# RP2350 register map
Vendor: Raspberry Pi; Series: RP; File version: 0.1
CPU: CM33 r1p0, little endian, MPU, FPU, DSP, VTOR, 4 interrupt priority bits, 52 interrupts, 8 SAU regions
Registers are 32-bit, read-write, reset 0x0 unless marked. A register's access mark holds for its fields unless they carry their own. Offsets are from the block's base; [hi:lo] are bit positions; {n}, {i} and the like mark numbered series; 'fields as' and 'values as' point back to an identical list.

## USB — USB FS/LS controller device registers
Base 0x50110000
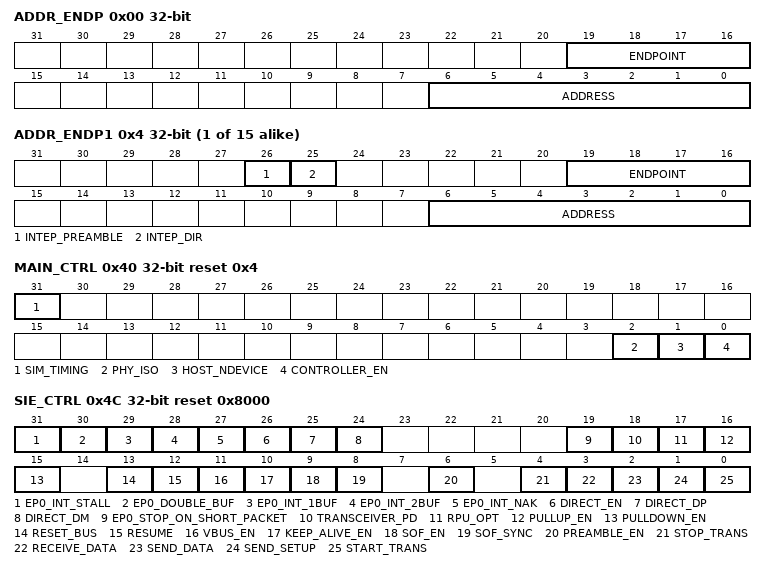
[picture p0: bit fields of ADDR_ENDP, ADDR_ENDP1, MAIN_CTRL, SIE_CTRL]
0x00 ADDR_ENDP — Device address and endpoint control
  [19:16] ENDPOINT — Device endpoint to send data to. Only valid for HOST mode.
  [6:0] ADDRESS — In device mode, the address that the device should respond to. Set in response to a SET_ADDR setup packet from the host. In host mode set to the address of the device to communicate with.
{0x0+4i} ADDR_ENDP{i} (i=1..15) — Interrupt endpoint {i}. Only valid for HOST mode.
  [26] INTEP_PREAMBLE — Interrupt EP requires preamble (is a low speed device on a full speed hub)
  [25] INTEP_DIR — Direction of the interrupt endpoint. In=0, Out=1
  [19:16] ENDPOINT — Endpoint number of the interrupt endpoint
  [6:0] ADDRESS — Device address
0x40 MAIN_CTRL reset 0x4 — Main control register
  [31] SIM_TIMING — Reduced timings for simulation
  [2] PHY_ISO — Isolates USB phy after controller power-up Remove isolation once software has configured the controller Not isolated = 0, Isolated = 1
  [1] HOST_NDEVICE — Device mode = 0, Host mode = 1
  [0] CONTROLLER_EN — Enable controller
0x44 SOF_WR — Set the SOF (Start of Frame) frame number in the host controller. The SOF packet is sent every 1ms and the host will increment the frame number by 1 each time.
  [10:0] COUNT wo — Pre-defined description
0x48 SOF_RD — Read the last SOF (Start of Frame) frame number seen. In device mode the last SOF received from the host. In host mode the last SOF sent by the host.
  [10:0] COUNT ro — Pre-defined description
0x4C SIE_CTRL reset 0x8000 — SIE control register
  [31] EP0_INT_STALL — Device: Set bit in EP_STATUS_STALL_NAK when EP0 sends a STALL
  [30] EP0_DOUBLE_BUF — Device: EP0 single buffered = 0, double buffered = 1
  [29] EP0_INT_1BUF — Device: Set bit in BUFF_STATUS for every buffer completed on EP0
  [28] EP0_INT_2BUF — Device: Set bit in BUFF_STATUS for every 2 buffers completed on EP0
  [27] EP0_INT_NAK — Device: Set bit in EP_STATUS_STALL_NAK when EP0 sends a NAK
  [26] DIRECT_EN — Direct bus drive enable
  [25] DIRECT_DP — Direct control of DP
  [24] DIRECT_DM — Direct control of DM
  [19] EP0_STOP_ON_SHORT_PACKET — Device: Stop EP0 on a short packet.
  [18] TRANSCEIVER_PD — Power down bus transceiver
  [17] RPU_OPT — Device: Pull-up strength (0=1K2, 1=2k3)
  [16] PULLUP_EN — Device: Enable pull up resistor
  [15] PULLDOWN_EN — Host: Enable pull down resistors
  [13] RESET_BUS wo — Host: Reset bus
  [12] RESUME wo — Device: Remote wakeup. Device can initiate its own resume after suspend.
  [11] VBUS_EN — Host: Enable VBUS
  [10] KEEP_ALIVE_EN — Host: Enable keep alive packet (for low speed bus)
  [9] SOF_EN — Host: Enable SOF generation (for full speed bus)
  [8] SOF_SYNC — Host: Delay packet(s) until after SOF
  [6] PREAMBLE_EN — Host: Preable enable for LS device on FS hub
  [4] STOP_TRANS wo — Host: Stop transaction
  [3] RECEIVE_DATA — Host: Receive transaction (IN to host)
  [2] SEND_DATA — Host: Send transaction (OUT from host)
  [1] SEND_SETUP — Host: Send Setup packet
  [0] START_TRANS wo — Host: Start transaction
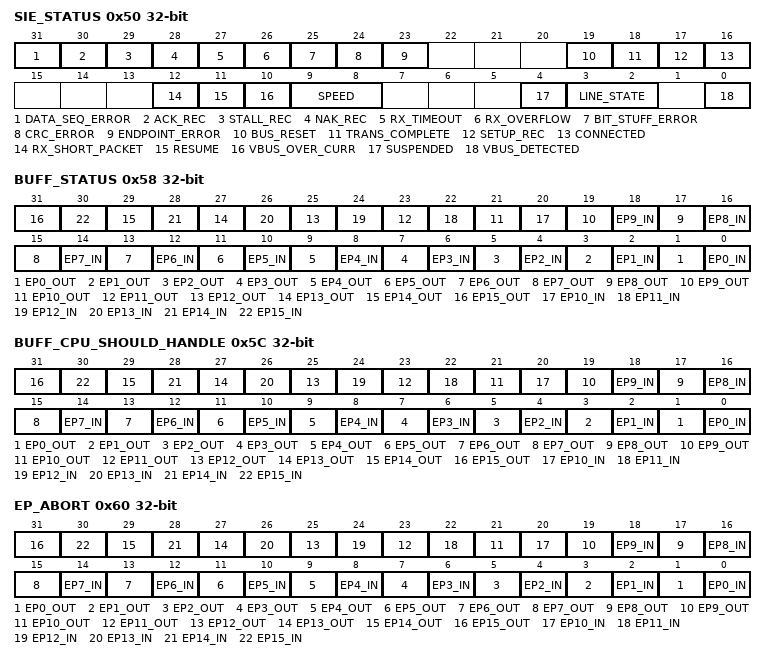
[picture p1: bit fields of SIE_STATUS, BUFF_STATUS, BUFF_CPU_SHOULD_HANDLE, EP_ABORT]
0x50 SIE_STATUS
  [31] DATA_SEQ_ERROR write-1-clears — Data Sequence Error. The device can raise a sequence error in the following conditions: * A SETUP packet is received followed by a DATA1 packet (data phase should always be DATA0) * An OUT packet is received from the host but doesn't match the data pid in the buffer control register read from DPSRAM The host can raise a data sequence error in the following conditions: * An IN packet from the device has the wrong data PID
  [30] ACK_REC write-1-clears — ACK received. Raised by both host and device.
  [29] STALL_REC write-1-clears — Host: STALL received
  [28] NAK_REC write-1-clears — Host: NAK received
  [27] RX_TIMEOUT write-1-clears — RX timeout is raised by both the host and device if an ACK is not received in the maximum time specified by the USB spec.
  [26] RX_OVERFLOW write-1-clears — RX overflow is raised by the Serial RX engine if the incoming data is too fast.
  [25] BIT_STUFF_ERROR write-1-clears — Bit Stuff Error. Raised by the Serial RX engine.
  [24] CRC_ERROR write-1-clears — CRC Error. Raised by the Serial RX engine.
  [23] ENDPOINT_ERROR write-1-clears — An endpoint has encountered an error. Read the ep_rx_error and ep_tx_error registers to find out which endpoint had an error.
  [19] BUS_RESET write-1-clears — Device: bus reset received
  [18] TRANS_COMPLETE write-1-clears — Transaction complete. Raised by device if: * An IN or OUT packet is sent with the `LAST_BUFF` bit set in the buffer control register Raised by host if: * A setup packet is sent when no data in or data out transaction follows * An IN packet is received and the `LAST_BUFF` bit is set in the buffer control register * An IN packet is received with zero length * An OUT packet is sent and the `LAST_BUFF` bit is set
  [17] SETUP_REC write-1-clears — Device: Setup packet received
  [16] CONNECTED ro — Device: connected
  [12] RX_SHORT_PACKET write-1-clears — Device or Host has received a short packet. This is when the data received is less than configured in the buffer control register. Device: If using double buffered mode on device the buffer select will not be toggled after writing status back to the buffer control register. This is to prevent any further transactions on that endpoint until the user has reset the buffer control registers. Host: the current transfer will be stopped early.
  [11] RESUME write-1-clears — Host: Device has initiated a remote resume. Device: host has initiated a resume.
  [10] VBUS_OVER_CURR ro — VBUS over current detected
  [9:8] SPEED ro — Host: device speed. Disconnected = 00, LS = 01, FS = 10
  [4] SUSPENDED write-1-clears — Bus in suspended state. Valid for device. Device will go into suspend if neither Keep Alive / SOF frames are enabled.
  [3:2] LINE_STATE ro — USB bus line state
  [0] VBUS_DETECTED ro — Device: VBUS Detected
0x54 INT_EP_CTRL — interrupt endpoint control register
  [15:1] INT_EP_ACTIVE — Host: Enable interrupt endpoint 1 -> 15
0x58 BUFF_STATUS — Buffer status register. A bit set here indicates that a buffer has completed on the endpoint (if the buffer interrupt is enabled). It is possible for 2 buffers to be completed, so clearing the buffer status bit may instantly re set it on the next clock cycle.
  [2n+1] EP{n}_OUT write-1-clears (n=0..15) — Pre-defined description
  [2n] EP{n}_IN write-1-clears (n=0..15) — Pre-defined description
0x5C BUFF_CPU_SHOULD_HANDLE — Which of the double buffers should be handled. Only valid if using an interrupt per buffer (i.e. not per 2 buffers). Not valid for host interrupt endpoint polling because they are only single buffered.
  [2n+1] EP{n}_OUT ro (n=0..15) — Pre-defined description
  [2n] EP{n}_IN ro (n=0..15) — Pre-defined description
0x60 EP_ABORT — Device only: Can be set to ignore the buffer control register for this endpoint in case you would like to revoke a buffer. A NAK will be sent for every access to the endpoint until this bit is cleared. A corresponding bit in `EP_ABORT_DONE` is set when it is safe to modify the buffer control register.
  [2n+1] EP{n}_OUT (n=0..15) — Pre-defined description
  [2n] EP{n}_IN (n=0..15) — Pre-defined description
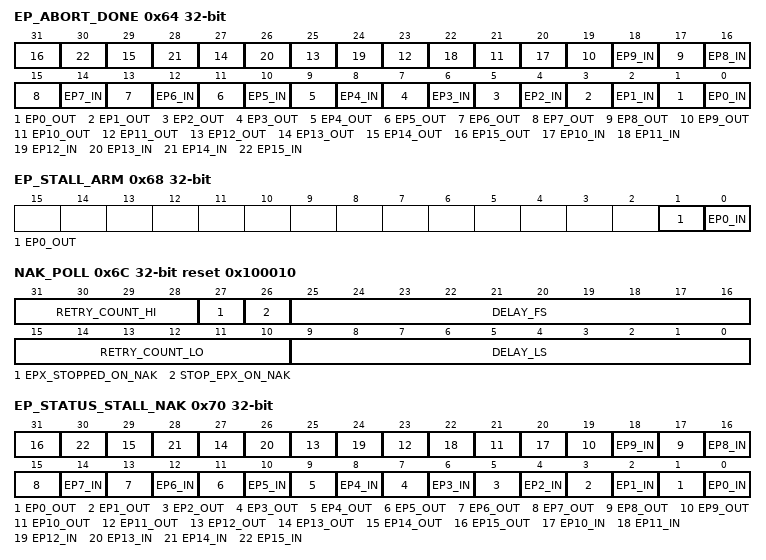
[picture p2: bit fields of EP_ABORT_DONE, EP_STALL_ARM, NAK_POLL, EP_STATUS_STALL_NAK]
0x64 EP_ABORT_DONE — Device only: Used in conjunction with `EP_ABORT`. Set once an endpoint is idle so the programmer knows it is safe to modify the buffer control register.
  fields as BUFF_STATUS
0x68 EP_STALL_ARM — Device: this bit must be set in conjunction with the `STALL` bit in the buffer control register to send a STALL on EP0. The device controller clears these bits when a SETUP packet is received because the USB spec requires that a STALL condition is cleared when a SETUP packet is received.
  [1] EP0_OUT — Pre-defined description
  [0] EP0_IN — Pre-defined description
0x6C NAK_POLL reset 0x100010 — Used by the host controller. Sets the wait time in microseconds before trying again if the device replies with a NAK.
  [31:28] RETRY_COUNT_HI ro — Bits 9:6 of nak_retry count
  [27] EPX_STOPPED_ON_NAK write-1-clears — EPX polling has stopped because a nak was received
  [26] STOP_EPX_ON_NAK — Stop polling epx when a nak is received
  [25:16] DELAY_FS — NAK polling interval for a full speed device
  [15:10] RETRY_COUNT_LO ro — Bits 5:0 of nak_retry_count
  [9:0] DELAY_LS — NAK polling interval for a low speed device
0x70 EP_STATUS_STALL_NAK — Device: bits are set when the `IRQ_ON_NAK` or `IRQ_ON_STALL` bits are set. For EP0 this comes from `SIE_CTRL`. For all other endpoints it comes from the endpoint control register.
  fields as BUFF_STATUS
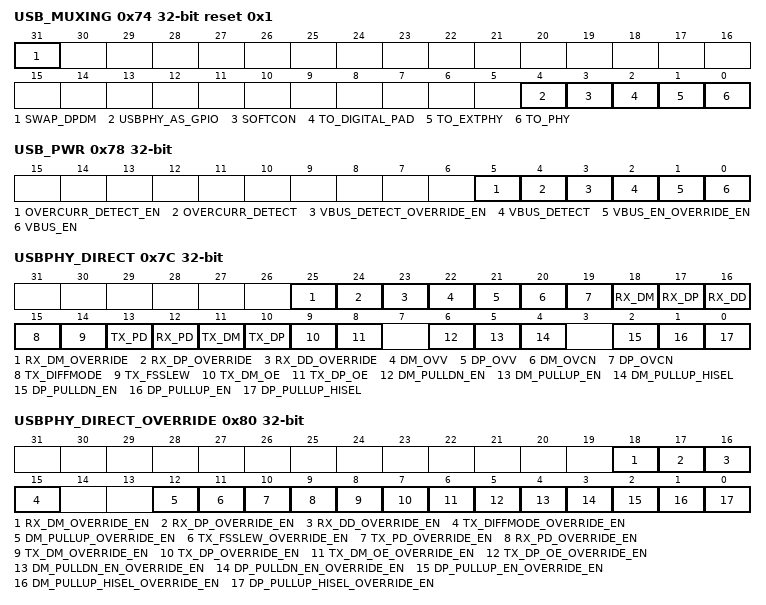
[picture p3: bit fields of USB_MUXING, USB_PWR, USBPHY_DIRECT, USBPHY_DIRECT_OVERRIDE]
0x74 USB_MUXING reset 0x1 — Where to connect the USB controller. Should be to_phy by default.
  [31] SWAP_DPDM — Swap the USB PHY DP and DM pins and all related controls and flip receive differential data. Can be used to switch USB DP/DP on the PCB. This is done at a low level so overrides all other controls.
  [4] USBPHY_AS_GPIO — Use the usb DP and DM pins as GPIO pins instead of connecting them to the USB controller.
  [3] SOFTCON — Pre-defined description
  [2] TO_DIGITAL_PAD — Pre-defined description
  [1] TO_EXTPHY — Pre-defined description
  [0] TO_PHY — Pre-defined description
0x78 USB_PWR — Overrides for the power signals in the event that the VBUS signals are not hooked up to GPIO. Set the value of the override and then the override enable to switch over to the override value.
  [5] OVERCURR_DETECT_EN — Pre-defined description
  [4] OVERCURR_DETECT — Pre-defined description
  [3] VBUS_DETECT_OVERRIDE_EN — Pre-defined description
  [2] VBUS_DETECT — Pre-defined description
  [1] VBUS_EN_OVERRIDE_EN — Pre-defined description
  [0] VBUS_EN — Pre-defined description
0x7C USBPHY_DIRECT — This register allows for direct control of the USB phy. Use in conjunction with usbphy_direct_override register to enable each override bit.
  [25] RX_DM_OVERRIDE — Override rx_dm value into controller
  [24] RX_DP_OVERRIDE — Override rx_dp value into controller
  [23] RX_DD_OVERRIDE — Override rx_dd value into controller
  [22] DM_OVV ro — DM over voltage
  [21] DP_OVV ro — DP over voltage
  [20] DM_OVCN ro — DM overcurrent
  [19] DP_OVCN ro — DP overcurrent
  [18] RX_DM ro — DPM pin state
  [17] RX_DP ro — DPP pin state
  [16] RX_DD ro — Differential RX
  [15] TX_DIFFMODE — TX_DIFFMODE=0: Single ended mode TX_DIFFMODE=1: Differential drive mode (TX_DM, TX_DM_OE ignored)
  [14] TX_FSSLEW — TX_FSSLEW=0: Low speed slew rate TX_FSSLEW=1: Full speed slew rate
  [13] TX_PD — TX power down override (if override enable is set). 1 = powered down.
  [12] RX_PD — RX power down override (if override enable is set). 1 = powered down.
  [11] TX_DM — Output data. TX_DIFFMODE=1, Ignored TX_DIFFMODE=0, Drives DPM only. TX_DM_OE=1 to enable drive. DPM=TX_DM
  [10] TX_DP — Output data. If TX_DIFFMODE=1, Drives DPP/DPM diff pair. TX_DP_OE=1 to enable drive. DPP=TX_DP, DPM=~TX_DP If TX_DIFFMODE=0, Drives DPP only. TX_DP_OE=1 to enable drive. DPP=TX_DP
  [9] TX_DM_OE — Output enable. If TX_DIFFMODE=1, Ignored. If TX_DIFFMODE=0, OE for DPM only. 0 - DPM in Hi-Z state; 1 - DPM driving
  [8] TX_DP_OE — Output enable. If TX_DIFFMODE=1, OE for DPP/DPM diff pair. 0 - DPP/DPM in Hi-Z state; 1 - DPP/DPM driving If TX_DIFFMODE=0, OE for DPP only. 0 - DPP in Hi-Z state; 1 - DPP driving
  [6] DM_PULLDN_EN — DM pull down enable
  [5] DM_PULLUP_EN — DM pull up enable
  [4] DM_PULLUP_HISEL — Enable the second DM pull up resistor. 0 - Pull = Rpu2; 1 - Pull = Rpu1 + Rpu2
  [2] DP_PULLDN_EN — DP pull down enable
  [1] DP_PULLUP_EN — DP pull up enable
  [0] DP_PULLUP_HISEL — Enable the second DP pull up resistor. 0 - Pull = Rpu2; 1 - Pull = Rpu1 + Rpu2
0x80 USBPHY_DIRECT_OVERRIDE — Override enable for each control in usbphy_direct
  [18] RX_DM_OVERRIDE_EN — Pre-defined description
  [17] RX_DP_OVERRIDE_EN — Pre-defined description
  [16] RX_DD_OVERRIDE_EN — Pre-defined description
  [15] TX_DIFFMODE_OVERRIDE_EN — Pre-defined description
  [12] DM_PULLUP_OVERRIDE_EN — Pre-defined description
  [11] TX_FSSLEW_OVERRIDE_EN — Pre-defined description
  [10] TX_PD_OVERRIDE_EN — Pre-defined description
  [9] RX_PD_OVERRIDE_EN — Pre-defined description
  [8] TX_DM_OVERRIDE_EN — Pre-defined description
  [7] TX_DP_OVERRIDE_EN — Pre-defined description
  [6] TX_DM_OE_OVERRIDE_EN — Pre-defined description
  [5] TX_DP_OE_OVERRIDE_EN — Pre-defined description
  [4] DM_PULLDN_EN_OVERRIDE_EN — Pre-defined description
  [3] DP_PULLDN_EN_OVERRIDE_EN — Pre-defined description
  [2] DP_PULLUP_EN_OVERRIDE_EN — Pre-defined description
  [1] DM_PULLUP_HISEL_OVERRIDE_EN — Pre-defined description
  [0] DP_PULLUP_HISEL_OVERRIDE_EN — Pre-defined description
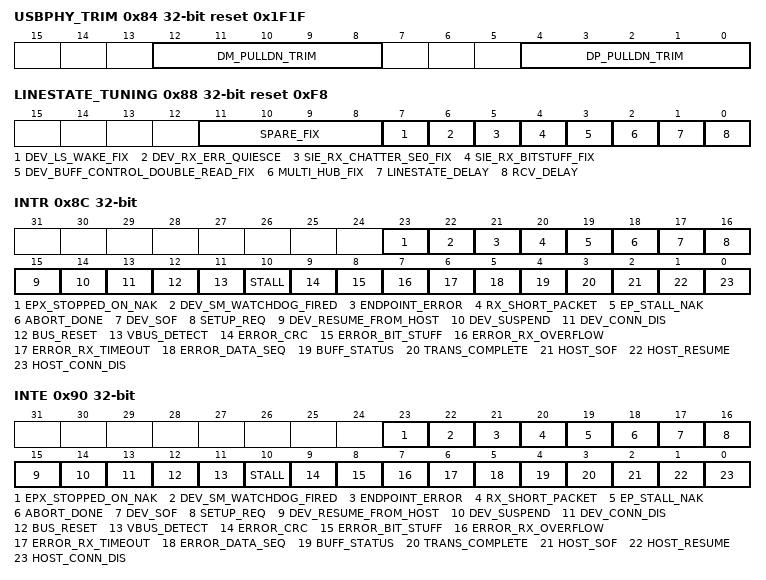
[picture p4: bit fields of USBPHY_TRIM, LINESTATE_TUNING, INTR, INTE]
0x84 USBPHY_TRIM reset 0x1F1F — Used to adjust trim values of USB phy pull down resistors.
  [12:8] DM_PULLDN_TRIM — Value to drive to USB PHY DM pulldown resistor trim control Experimental data suggests that the reset value will work, but this register allows adjustment if required
  [4:0] DP_PULLDN_TRIM — Value to drive to USB PHY DP pulldown resistor trim control Experimental data suggests that the reset value will work, but this register allows adjustment if required
0x88 LINESTATE_TUNING reset 0xF8 — Used for debug only.
  [11:8] SPARE_FIX — Pre-defined description
  [7] DEV_LS_WAKE_FIX — Device - exit suspend on any non-idle signalling, not qualified with a 1ms timer
  [6] DEV_RX_ERR_QUIESCE — Device - suppress repeated errors until the device FSM is next in the process of decoding an inbound packet.
  [5] SIE_RX_CHATTER_SE0_FIX — RX - when recovering from line chatter or bitstuff errors, treat SE0 as the end of chatter as well as 8 consecutive idle bits.
  [4] SIE_RX_BITSTUFF_FIX — RX - when a bitstuff error is signalled by rx_dasm, unconditionally terminate RX decode to avoid a hang during certain packet phases.
  [3] DEV_BUFF_CONTROL_DOUBLE_READ_FIX — Device - the controller FSM performs two reads of the buffer status memory address to avoid sampling metastable data. An enabled buffer is only used if both reads match.
  [2] MULTI_HUB_FIX — Host - increase inter-packet and turnaround timeouts to accommodate worst-case hub delays.
  [1] LINESTATE_DELAY — Device/Host - add an extra 1-bit debounce of linestate sampling.
  [0] RCV_DELAY — Device - register the received data to account for hub bit dribble before EOP. Only affects certain hubs.
0x8C INTR — Raw Interrupts
  [23] EPX_STOPPED_ON_NAK ro — Source: NAK_POLL.EPX_STOPPED_ON_NAK
  [22] DEV_SM_WATCHDOG_FIRED ro — Source: DEV_SM_WATCHDOG.FIRED
  [21] ENDPOINT_ERROR ro — Source: SIE_STATUS.ENDPOINT_ERROR
  [20] RX_SHORT_PACKET ro — Source: SIE_STATUS.RX_SHORT_PACKET
  [19] EP_STALL_NAK ro — Raised when any bit in EP_STATUS_STALL_NAK is set. Clear by clearing all bits in EP_STATUS_STALL_NAK.
  [18] ABORT_DONE ro — Raised when any bit in ABORT_DONE is set. Clear by clearing all bits in ABORT_DONE.
  [17] DEV_SOF ro — Set every time the device receives a SOF (Start of Frame) packet. Cleared by reading SOF_RD
  [16] SETUP_REQ ro — Device. Source: SIE_STATUS.SETUP_REC
  [15] DEV_RESUME_FROM_HOST ro — Set when the device receives a resume from the host. Cleared by writing to SIE_STATUS.RESUME
  [14] DEV_SUSPEND ro — Set when the device suspend state changes. Cleared by writing to SIE_STATUS.SUSPENDED
  [13] DEV_CONN_DIS ro — Set when the device connection state changes. Cleared by writing to SIE_STATUS.CONNECTED
  [12] BUS_RESET ro — Source: SIE_STATUS.BUS_RESET
  [11] VBUS_DETECT ro — Source: SIE_STATUS.VBUS_DETECTED
  [10] STALL ro — Source: SIE_STATUS.STALL_REC
  [9] ERROR_CRC ro — Source: SIE_STATUS.CRC_ERROR
  [8] ERROR_BIT_STUFF ro — Source: SIE_STATUS.BIT_STUFF_ERROR
  [7] ERROR_RX_OVERFLOW ro — Source: SIE_STATUS.RX_OVERFLOW
  [6] ERROR_RX_TIMEOUT ro — Source: SIE_STATUS.RX_TIMEOUT
  [5] ERROR_DATA_SEQ ro — Source: SIE_STATUS.DATA_SEQ_ERROR
  [4] BUFF_STATUS ro — Raised when any bit in BUFF_STATUS is set. Clear by clearing all bits in BUFF_STATUS.
  [3] TRANS_COMPLETE ro — Raised every time SIE_STATUS.TRANS_COMPLETE is set. Clear by writing to this bit.
  [2] HOST_SOF ro — Host: raised every time the host sends a SOF (Start of Frame). Cleared by reading SOF_RD
  [1] HOST_RESUME ro — Host: raised when a device wakes up the host. Cleared by writing to SIE_STATUS.RESUME
  [0] HOST_CONN_DIS ro — Host: raised when a device is connected or disconnected (i.e. when SIE_STATUS.SPEED changes). Cleared by writing to SIE_STATUS.SPEED
0x90 INTE — Interrupt Enable
  [23] EPX_STOPPED_ON_NAK — Source: NAK_POLL.EPX_STOPPED_ON_NAK
  [22] DEV_SM_WATCHDOG_FIRED — Source: DEV_SM_WATCHDOG.FIRED
  [21] ENDPOINT_ERROR — Source: SIE_STATUS.ENDPOINT_ERROR
  [20] RX_SHORT_PACKET — Source: SIE_STATUS.RX_SHORT_PACKET
  [19] EP_STALL_NAK — Raised when any bit in EP_STATUS_STALL_NAK is set. Clear by clearing all bits in EP_STATUS_STALL_NAK.
  [18] ABORT_DONE — Raised when any bit in ABORT_DONE is set. Clear by clearing all bits in ABORT_DONE.
  [17] DEV_SOF — Set every time the device receives a SOF (Start of Frame) packet. Cleared by reading SOF_RD
  [16] SETUP_REQ — Device. Source: SIE_STATUS.SETUP_REC
  [15] DEV_RESUME_FROM_HOST — Set when the device receives a resume from the host. Cleared by writing to SIE_STATUS.RESUME
  [14] DEV_SUSPEND — Set when the device suspend state changes. Cleared by writing to SIE_STATUS.SUSPENDED
  [13] DEV_CONN_DIS — Set when the device connection state changes. Cleared by writing to SIE_STATUS.CONNECTED
  [12] BUS_RESET — Source: SIE_STATUS.BUS_RESET
  [11] VBUS_DETECT — Source: SIE_STATUS.VBUS_DETECTED
  [10] STALL — Source: SIE_STATUS.STALL_REC
  [9] ERROR_CRC — Source: SIE_STATUS.CRC_ERROR
  [8] ERROR_BIT_STUFF — Source: SIE_STATUS.BIT_STUFF_ERROR
  [7] ERROR_RX_OVERFLOW — Source: SIE_STATUS.RX_OVERFLOW
  [6] ERROR_RX_TIMEOUT — Source: SIE_STATUS.RX_TIMEOUT
  [5] ERROR_DATA_SEQ — Source: SIE_STATUS.DATA_SEQ_ERROR
  [4] BUFF_STATUS — Raised when any bit in BUFF_STATUS is set. Clear by clearing all bits in BUFF_STATUS.
  [3] TRANS_COMPLETE — Raised every time SIE_STATUS.TRANS_COMPLETE is set. Clear by writing to this bit.
  [2] HOST_SOF — Host: raised every time the host sends a SOF (Start of Frame). Cleared by reading SOF_RD
  [1] HOST_RESUME — Host: raised when a device wakes up the host. Cleared by writing to SIE_STATUS.RESUME
  [0] HOST_CONN_DIS — Host: raised when a device is connected or disconnected (i.e. when SIE_STATUS.SPEED changes). Cleared by writing to SIE_STATUS.SPEED
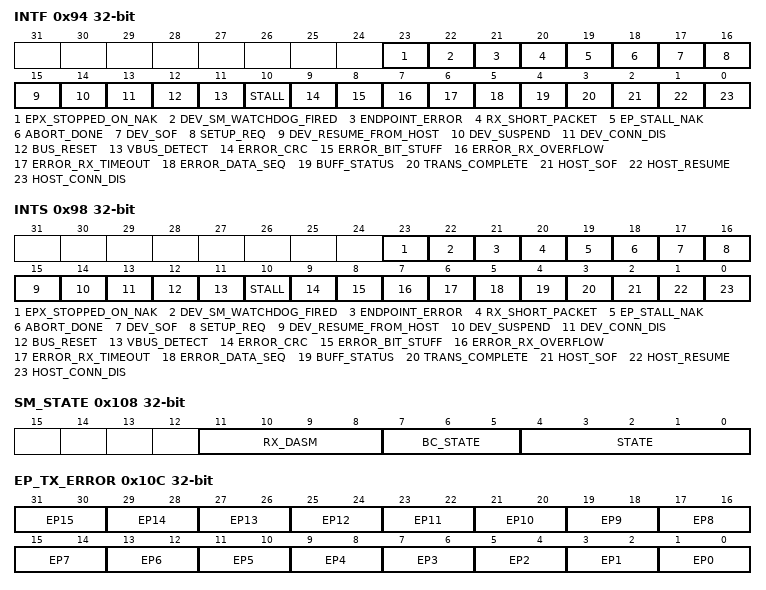
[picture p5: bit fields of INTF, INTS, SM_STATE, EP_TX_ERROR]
0x94 INTF — Interrupt Force
  fields as INTE
0x98 INTS — Interrupt status after masking & forcing
  fields as INTR
0x100 SOF_TIMESTAMP_RAW — Device only. Raw value of free-running PHY clock counter @48MHz. Used to calculate time between SOF events.
  [20:0] SOF_TIMESTAMP_RAW ro — Pre-defined description
0x104 SOF_TIMESTAMP_LAST — Device only. Value of free-running PHY clock counter @48MHz when last SOF event occurred.
  [20:0] SOF_TIMESTAMP_LAST ro — Pre-defined description
0x108 SM_STATE — register description
  [11:8] RX_DASM ro — Pre-defined description
  [7:5] BC_STATE ro — Pre-defined description
  [4:0] STATE ro — Pre-defined description
0x10C EP_TX_ERROR — TX error count for each endpoint. Write to each field to reset the counter to 0.
  [2n+1:2n] EP{n} write-1-clears (n=0..15) — Pre-defined description
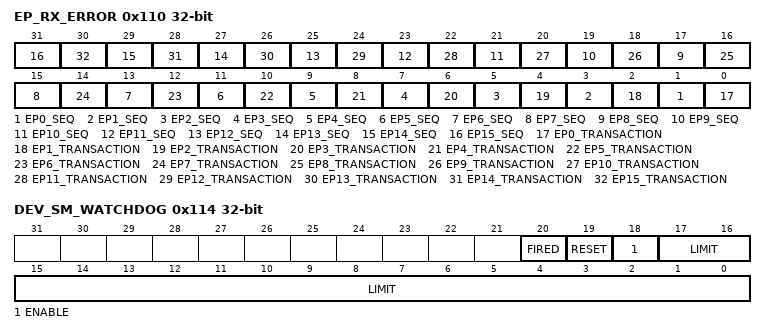
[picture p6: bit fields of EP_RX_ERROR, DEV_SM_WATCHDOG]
0x110 EP_RX_ERROR — RX error count for each endpoint. Write to each field to reset the counter to 0.
  [2n+1] EP{n}_SEQ write-1-clears (n=0..15) — Pre-defined description
  [2n] EP{n}_TRANSACTION write-1-clears (n=0..15) — Pre-defined description
0x114 DEV_SM_WATCHDOG — Watchdog that forces the device state machine to idle and raises an interrupt if the device stays in a state that isn't idle for the configured limit. The counter is reset on every state transition. Set limit while enable is low and then set the enable.
  [20] FIRED write-1-clears — Pre-defined description
  [19] RESET — Set to 1 to forcibly reset the device state machine on watchdog expiry
  [18] ENABLE — Pre-defined description
  [17:0] LIMIT — Pre-defined description
